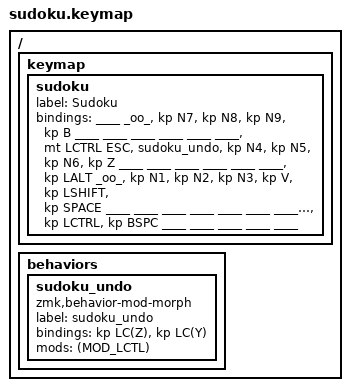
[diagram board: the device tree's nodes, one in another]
/ {
    keymap {
        sudoku {
			label = "Sudoku";
			bindings = <
//                ╭─────────┬──────────────┬─────┬─────┬─────┬─────╮                           ╭─────┬─────┬─────┬─────┬─────┬─────╮
//                │         │     ---      │  7  │  8  │  9  │  V  │                           │     │     │     │     │     │     │
//                ├─────────┼──────────────┼─────┼─────┼─────┼─────┤                           ├─────┼─────┼─────┼─────┼─────┼─────┤
//                │  ⌃ │ ⎋  │ &sudoku_undo │  4  │  5  │  6  │  Z  │                           │     │     │     │     │     │     │
//                ├─────────┼──────────────┼─────┼─────┼─────┼─────┼─────┬─────╮   ╭─────┬─────┼─────┼─────┼─────┼─────┼─────┼─────┤
//                │    ⎇    │     ---      │  1  │  2  │  3  │  B  │  ⇧  │  ␣  │   │     │     │     │     │     │     │     │     │
//                ╰─────────┴──────────────┴─────┼─────┼─────┼─────┼─────┼─────┤   ├─────┼─────┼─────┼─────┼─────┼─────┴─────┴─────╯
//                                               │     │     │     │  ⌃  │  ⌫  │   │     │     │     │     │     │                  
//                                               ╰─────┴─────┴─────┴─────┴─────╯   ╰─────┴─────┴─────┴─────┴─────╯                  
              ____            _oo_           &kp N7   &kp N8   &kp N9   &kp B                                              ____   ____   ____   ____   ____   ____
              &mt LCTRL ESC   &sudoku_undo   &kp N4   &kp N5   &kp N6   &kp Z                                              ____   ____   ____   ____   ____   ____
              &kp LALT        _oo_           &kp N1   &kp N2   &kp N3   &kp V   &kp LSHIFT   &kp SPACE       ____   ____   ____   ____   ____   ____   ____   ____
                                                      ____     ____     ____    &kp LCTRL    &kp BSPC        ____   ____   ____   ____   ____                     
            >;
        };
    };

    behaviors {
        sudoku_undo: sudoku_undo {
            compatible = "zmk,behavior-mod-morph";
            label = "sudoku_undo";
            bindings = <&kp LC(Z)>, <&kp LC(Y)>;
            #binding-cells = <0>;
            mods = <(MOD_LCTL)>;
        };
    };
};
